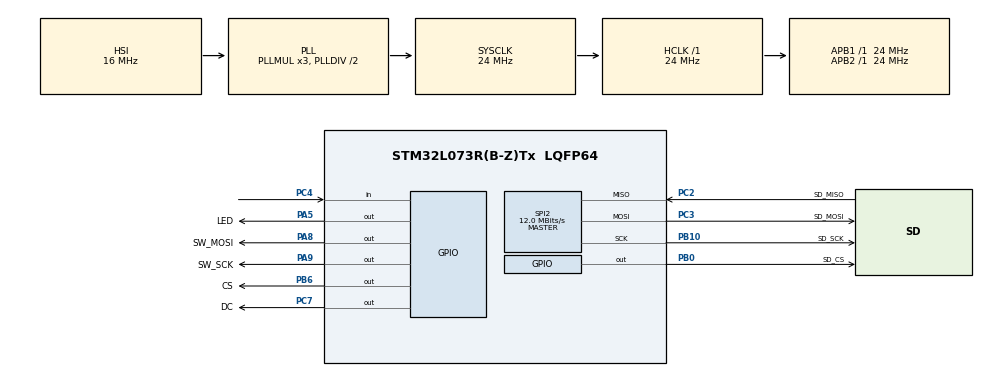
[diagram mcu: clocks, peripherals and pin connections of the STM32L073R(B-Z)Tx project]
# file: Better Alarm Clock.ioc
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FREERTOS.INCLUDE_uxTaskGetStackHighWaterMark=1
FREERTOS.INCLUDE_xEventGroupSetBitFromISR=1
FREERTOS.INCLUDE_xTimerPendFunctionCall=1
FREERTOS.MEMORY_ALLOCATION=1
FREERTOS.Tasks01=soundTask,3,128,soundTaskEntry,Default,NULL,Static,soundTaskBuffer,soundTaskControlBlock;guiTask,0,1024,guiTaskEntry,Default,NULL,Static,guiTaskBuffer,guiTaskControlBlock
FREERTOS.configCHECK_FOR_STACK_OVERFLOW=2
FREERTOS.configENABLE_BACKWARD_COMPATIBILITY=0
FREERTOS.configUSE_PREEMPTION=0
FREERTOS.configUSE_TASK_NOTIFICATIONS=0
FREERTOS.configUSE_TICKLESS_IDLE=1
FREERTOS.configUSE_TIMERS=1
Mcu.Family=STM32L0
Mcu.Name=STM32L073R(B-Z)Tx
Mcu.Package=LQFP64
NVIC.RTC_IRQn=true\:0\:0\:false\:false\:true\:false\:true
NVIC.TIM2_IRQn=true\:0\:0\:false\:false\:true\:false\:false
NVIC.TimeBase=TIM2_IRQn
NVIC.TimeBaseIP=TIM2
PA13.Mode=Serial_Wire
PA13.Signal=SYS_SWDIO
PA14.Mode=Serial_Wire
PA14.Signal=SYS_SWCLK
PA5.GPIO_Label=LED
PA5.Signal=GPIO_Output
PA8.GPIO_Label=SW_MOSI
PA8.Signal=GPIO_Output
PA9.GPIO_Label=SW_SCK
PA9.GPIO_PuPd=GPIO_PULLDOWN
PA9.GPIO_Speed=GPIO_SPEED_FREQ_VERY_HIGH
PA9.Signal=GPIO_Output
PB0.GPIO_Label=SD_CS
PB0.Signal=GPIO_Output
PB10.GPIO_Label=SD_SCK
PB10.Mode=Full_Duplex_Master
PB10.Signal=SPI2_SCK
PB6.GPIO_Label=CS
PB6.Signal=GPIO_Output
PC14-OSC32_IN.Mode=LSE-External-Oscillator
PC14-OSC32_IN.Signal=RCC_OSC32_IN
PC15-OSC32_OUT.Mode=LSE-External-Oscillator
PC15-OSC32_OUT.Signal=RCC_OSC32_OUT
PC2.GPIO_Label=SD_MISO
PC2.Mode=Full_Duplex_Master
PC2.Signal=SPI2_MISO
PC3.GPIO_Label=SD_MOSI
PC3.Mode=Full_Duplex_Master
PC3.Signal=SPI2_MOSI
PC4.Signal=GPIO_Input
PC7.GPIO_Label=DC
PC7.Signal=GPIO_Output
ProjectManager.HeapSize=0x200
ProjectManager.StackSize=0x400
ProjectManager.TargetToolchain=SW4STM32
RCC.AHBFreq_Value=24000000
RCC.APB1Freq_Value=24000000
RCC.APB1TimFreq_Value=24000000
RCC.APB2Freq_Value=24000000
RCC.APB2TimFreq_Value=24000000
RCC.HCLKFreq_Value=24000000
RCC.HSE_VALUE=8000000
RCC.HSI16_VALUE=16000000
RCC.HSI48_VALUE=48000000
RCC.HSI_VALUE=16000000
RCC.MSI_VALUE=2097000
RCC.RTCClockSelectionVirtual=RCC_RTCCLKSOURCE_LSE
RCC.SYSCLKFreq_VALUE=24000000
RCC.SYSCLKSource=RCC_SYSCLKSOURCE_PLLCLK
RCC.VCOOutputFreq_Value=48000000
RTC.Alarm-Alarm\ A=RTC_ALARM_A
RTC.AlarmMaskDateWeekDay-Alarm\ A=RTC_ALARMMASK_DATEWEEKDAY
RTC.AlarmMaskHours-Alarm\ A=RTC_ALARMMASK_HOURS
RTC.AlarmMaskMinutes-Alarm\ A=RTC_ALARMMASK_MINUTES
RTC.AlarmMaskSeconds-Alarm\ A=RTC_ALARMMASK_SECONDS
RTC.Alarm_B-Alarm\ B=RTC_ALARM_B
RTC.Format=RTC_FORMAT_BIN
SPI2.CalculateBaudRate=12.0 MBits/s
SPI2.Direction=SPI_DIRECTION_2LINES
SPI2.Mode=SPI_MODE_MASTER
SPI2.VirtualType=VM_MASTER
VP_FATFS_VS_Generic.Mode=User_defined
VP_FREERTOS_VS_ENABLE.Mode=Enabled
VP_RTC_VS_RTC_Activate.Mode=RTC_Enabled
VP_RTC_VS_RTC_Alarm_A_Intern.Mode=Alarm A
VP_RTC_VS_RTC_Alarm_B_Intern.Mode=Alarm B
VP_RTC_VS_RTC_Calendar.Mode=RTC_Calendar
VP_SYS_VS_tim2.Mode=TIM2
board=Better Alarm Clock

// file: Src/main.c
/**
  ******************************************************************************
  * File Name          : main.c
  * Description        : Main program body
  ******************************************************************************
  * This notice applies to any and all portions of this file
  * that are not between comment pairs USER CODE BEGIN and
  * USER CODE END. Other portions of this file, whether
  * inserted by the user or by software development tools
  * are owned by their respective copyright owners.
  *
  * Copyright (c) 2018 STMicroelectronics International N.V.
  * All rights reserved.
  *
  * Redistribution and use in source and binary forms, with or without
  * modification, are permitted, provided that the following conditions are met:
  *
  * 1. Redistribution of source code must retain the above copyright notice,
  *    this list of conditions and the following disclaimer.
  * 2. Redistributions in binary form must reproduce the above copyright notice,
  *    this list of conditions and the following disclaimer in the documentation
  *    and/or other materials provided with the distribution.
  * 3. Neither the name of STMicroelectronics nor the names of other
  *    contributors to this software may be used to endorse or promote products
  *    derived from this software without specific written permission.
  * 4. This software, including modifications and/or derivative works of this
  *    software, must execute solely and exclusively on microcontroller or
  *    microprocessor devices manufactured by or for STMicroelectronics.
  * 5. Redistribution and use of this software other than as permitted under
  *    this license is void and will automatically terminate your rights under
  *    this license.
  *
  * THIS SOFTWARE IS PROVIDED BY STMICROELECTRONICS AND CONTRIBUTORS "AS IS"
  * AND ANY EXPRESS, IMPLIED OR STATUTORY WARRANTIES, INCLUDING, BUT NOT
  * LIMITED TO, THE IMPLIED WARRANTIES OF MERCHANTABILITY, FITNESS FOR A
  * PARTICULAR PURPOSE AND NON-INFRINGEMENT OF THIRD PARTY INTELLECTUAL PROPERTY
  * RIGHTS ARE DISCLAIMED TO THE FULLEST EXTENT PERMITTED BY LAW. IN NO EVENT
  * SHALL STMICROELECTRONICS OR CONTRIBUTORS BE LIABLE FOR ANY DIRECT, INDIRECT,
  * INCIDENTAL, SPECIAL, EXEMPLARY, OR CONSEQUENTIAL DAMAGES (INCLUDING, BUT NOT
  * LIMITED TO, PROCUREMENT OF SUBSTITUTE GOODS OR SERVICES; LOSS OF USE, DATA,
  * OR PROFITS; OR BUSINESS INTERRUPTION) HOWEVER CAUSED AND ON ANY THEORY OF
  * LIABILITY, WHETHER IN CONTRACT, STRICT LIABILITY, OR TORT (INCLUDING
  * NEGLIGENCE OR OTHERWISE) ARISING IN ANY WAY OUT OF THE USE OF THIS SOFTWARE,
  * EVEN IF ADVISED OF THE POSSIBILITY OF SUCH DAMAGE.
  *
  ******************************************************************************
  */

#include "main.h"
#include "stm32l0xx_hal.h"
#include "cmsis_os.h"
#include "fatfs.h"

/* USER CODE BEGIN Includes */
#include "display_hw.h"
#include "application.h"
#include <stdio.h>	/*rtt*/
#include <stdlib.h>	/*rtt*/

/* USER CODE END Includes */

RTC_HandleTypeDef hrtc;

SPI_HandleTypeDef hspi2;

osThreadId soundTaskHandle;
uint32_t soundTaskBuffer[ 128 ];
osStaticThreadDef_t soundTaskControlBlock;
osThreadId guiTaskHandle;
uint32_t guiTaskBuffer[ 1024 ];
osStaticThreadDef_t guiTaskControlBlock;

/* USER CODE BEGIN PV */
/* Private variables ---------------------------------------------------------*/

/* USER CODE END PV */

void SystemClock_Config(void);
static void MX_GPIO_Init(void);
static void MX_RTC_Init(void);
static void MX_SPI2_Init(void);
void soundTaskEntry(void const * argument);
void guiTaskEntry(void const * argument);

/* USER CODE BEGIN PFP */
/* Private function prototypes -----------------------------------------------*/
extern void initialise_monitor_handles(void);	/*rtt*/
/* USER CODE END PFP */

int main(void)
{

  /* USER CODE BEGIN 1 */
  initialise_monitor_handles();

  puts("ARM semihosting enabled.");

  /* USER CODE END 1 */

  /* MCU Configuration----------------------------------------------------------*/

  /* Reset of all peripherals, Initializes the Flash interface and the Systick. */
  HAL_Init();

  /* Configure the system clock */
  SystemClock_Config();

  /* Initialize all configured peripherals */
  MX_GPIO_Init();
  MX_RTC_Init();
  MX_SPI2_Init();

  /* USER CODE BEGIN 2 */
  initDisplay();
  /* USER CODE END 2 */

  /* Create the thread(s) */
  /* definition and creation of soundTask */
  osThreadStaticDef(soundTask, soundTaskEntry, osPriorityRealtime, 0, 128, soundTaskBuffer, &soundTaskControlBlock);
  soundTaskHandle = osThreadCreate(osThread(soundTask), NULL);

  /* definition and creation of guiTask */
  osThreadStaticDef(guiTask, guiTaskEntry, osPriorityNormal, 0, 1024, guiTaskBuffer, &guiTaskControlBlock);
  guiTaskHandle = osThreadCreate(osThread(guiTask), NULL);

  /* Start scheduler */
  osKernelStart();

  /* We should never get here as control is now taken by the scheduler */

  /* Infinite loop */
  while (1)
  {

  }

}

/** System Clock Configuration
*/
void SystemClock_Config(void)
{

  RCC_OscInitTypeDef RCC_OscInitStruct;
  RCC_ClkInitTypeDef RCC_ClkInitStruct;
  RCC_PeriphCLKInitTypeDef PeriphClkInit;

    /**Configure the main internal regulator output voltage
    */
  __HAL_PWR_VOLTAGESCALING_CONFIG(PWR_REGULATOR_VOLTAGE_SCALE1);

    /**Configure LSE Drive Capability
    */
  __HAL_RCC_LSEDRIVE_CONFIG(RCC_LSEDRIVE_LOW);

    /**Initializes the CPU, AHB and APB busses clocks
    */
  RCC_OscInitStruct.OscillatorType = RCC_OSCILLATORTYPE_HSI|RCC_OSCILLATORTYPE_LSE;
  RCC_OscInitStruct.LSEState = RCC_LSE_ON;
  RCC_OscInitStruct.HSIState = RCC_HSI_ON;
  RCC_OscInitStruct.HSICalibrationValue = 16;
  RCC_OscInitStruct.PLL.PLLState = RCC_PLL_ON;
  RCC_OscInitStruct.PLL.PLLSource = RCC_PLLSOURCE_HSI;
  RCC_OscInitStruct.PLL.PLLMUL = RCC_PLLMUL_3;
  RCC_OscInitStruct.PLL.PLLDIV = RCC_PLLDIV_2;
  if (HAL_RCC_OscConfig(&RCC_OscInitStruct) != HAL_OK)
  {
    _Error_Handler(__FILE__, __LINE__);
  }

    /**Initializes the CPU, AHB and APB busses clocks
    */
  RCC_ClkInitStruct.ClockType = RCC_CLOCKTYPE_HCLK|RCC_CLOCKTYPE_SYSCLK
                              |RCC_CLOCKTYPE_PCLK1|RCC_CLOCKTYPE_PCLK2;
  RCC_ClkInitStruct.SYSCLKSource = RCC_SYSCLKSOURCE_PLLCLK;
  RCC_ClkInitStruct.AHBCLKDivider = RCC_SYSCLK_DIV1;
  RCC_ClkInitStruct.APB1CLKDivider = RCC_HCLK_DIV1;
  RCC_ClkInitStruct.APB2CLKDivider = RCC_HCLK_DIV1;

  if (HAL_RCC_ClockConfig(&RCC_ClkInitStruct, FLASH_LATENCY_1) != HAL_OK)
  {
    _Error_Handler(__FILE__, __LINE__);
  }

  PeriphClkInit.PeriphClockSelection = RCC_PERIPHCLK_RTC;
  PeriphClkInit.RTCClockSelection = RCC_RTCCLKSOURCE_LSE;
  if (HAL_RCCEx_PeriphCLKConfig(&PeriphClkInit) != HAL_OK)
  {
    _Error_Handler(__FILE__, __LINE__);
  }

    /**Configure the Systick interrupt time
    */
  HAL_SYSTICK_Config(HAL_RCC_GetHCLKFreq()/1000);

    /**Configure the Systick
    */
  HAL_SYSTICK_CLKSourceConfig(SYSTICK_CLKSOURCE_HCLK);

  /* SysTick_IRQn interrupt configuration */
  HAL_NVIC_SetPriority(SysTick_IRQn, 3, 0);
}

/* RTC init function */
static void MX_RTC_Init(void)
{

  RTC_TimeTypeDef sTime;
  RTC_DateTypeDef sDate;
  RTC_AlarmTypeDef sAlarm;

    /**Initialize RTC Only
    */
  hrtc.Instance = RTC;
  hrtc.Init.HourFormat = RTC_HOURFORMAT_24;
  hrtc.Init.AsynchPrediv = 127;
  hrtc.Init.SynchPrediv = 255;
  hrtc.Init.OutPut = RTC_OUTPUT_DISABLE;
  hrtc.Init.OutPutRemap = RTC_OUTPUT_REMAP_NONE;
  hrtc.Init.OutPutPolarity = RTC_OUTPUT_POLARITY_HIGH;
  hrtc.Init.OutPutType = RTC_OUTPUT_TYPE_OPENDRAIN;
  if (HAL_RTC_Init(&hrtc) != HAL_OK)
  {
    _Error_Handler(__FILE__, __LINE__);
  }

    /**Initialize RTC and set the Time and Date
    */
  if(HAL_RTCEx_BKUPRead(&hrtc, RTC_BKP_DR0) != 0x32F2){
  sTime.Hours = 0;
  sTime.Minutes = 0;
  sTime.Seconds = 0;
  sTime.DayLightSaving = RTC_DAYLIGHTSAVING_NONE;
  sTime.StoreOperation = RTC_STOREOPERATION_RESET;
  if (HAL_RTC_SetTime(&hrtc, &sTime, RTC_FORMAT_BIN) != HAL_OK)
  {
    _Error_Handler(__FILE__, __LINE__);
  }

  sDate.WeekDay = RTC_WEEKDAY_MONDAY;
  sDate.Month = RTC_MONTH_JANUARY;
  sDate.Date = 1;
  sDate.Year = 0;

  if (HAL_RTC_SetDate(&hrtc, &sDate, RTC_FORMAT_BIN) != HAL_OK)
  {
    _Error_Handler(__FILE__, __LINE__);
  }

    HAL_RTCEx_BKUPWrite(&hrtc,RTC_BKP_DR0,0x32F2);
  }
    /**Enable the Alarm A
    */
  sAlarm.AlarmTime.Hours = 0;
  sAlarm.AlarmTime.Minutes = 0;
  sAlarm.AlarmTime.Seconds = 0;
  sAlarm.AlarmTime.SubSeconds = 0;
  sAlarm.AlarmTime.DayLightSaving = RTC_DAYLIGHTSAVING_NONE;
  sAlarm.AlarmTime.StoreOperation = RTC_STOREOPERATION_RESET;
  sAlarm.AlarmMask = RTC_ALARMMASK_ALL;
  sAlarm.AlarmSubSecondMask = RTC_ALARMSUBSECONDMASK_ALL;
  sAlarm.AlarmDateWeekDaySel = RTC_ALARMDATEWEEKDAYSEL_DATE;
  sAlarm.AlarmDateWeekDay = 1;
  sAlarm.Alarm = RTC_ALARM_A;
  if (HAL_RTC_SetAlarm_IT(&hrtc, &sAlarm, RTC_FORMAT_BIN) != HAL_OK)
  {
    _Error_Handler(__FILE__, __LINE__);
  }

    /**Enable the Alarm B
    */
  sAlarm.AlarmMask = RTC_ALARMMASK_NONE;
  sAlarm.AlarmDateWeekDay = 1;
  sAlarm.Alarm = RTC_ALARM_B;
  if (HAL_RTC_SetAlarm_IT(&hrtc, &sAlarm, RTC_FORMAT_BIN) != HAL_OK)
  {
    _Error_Handler(__FILE__, __LINE__);
  }

}

/* SPI2 init function */
static void MX_SPI2_Init(void)
{

  /* SPI2 parameter configuration*/
  hspi2.Instance = SPI2;
  hspi2.Init.Mode = SPI_MODE_MASTER;
  hspi2.Init.Direction = SPI_DIRECTION_2LINES;
  hspi2.Init.DataSize = SPI_DATASIZE_8BIT;
  hspi2.Init.CLKPolarity = SPI_POLARITY_LOW;
  hspi2.Init.CLKPhase = SPI_PHASE_1EDGE;
  hspi2.Init.NSS = SPI_NSS_SOFT;
  hspi2.Init.BaudRatePrescaler = SPI_BAUDRATEPRESCALER_2;
  hspi2.Init.FirstBit = SPI_FIRSTBIT_MSB;
  hspi2.Init.TIMode = SPI_TIMODE_DISABLE;
  hspi2.Init.CRCCalculation = SPI_CRCCALCULATION_DISABLE;
  hspi2.Init.CRCPolynomial = 7;
  if (HAL_SPI_Init(&hspi2) != HAL_OK)
  {
    _Error_Handler(__FILE__, __LINE__);
  }

}

/** Configure pins as
        * Analog
        * Input
        * Output
        * EVENT_OUT
        * EXTI
        * Free pins are configured automatically as Analog (this feature is enabled through
        * the Code Generation settings)
*/
static void MX_GPIO_Init(void)
{

  GPIO_InitTypeDef GPIO_InitStruct;

  /* GPIO Ports Clock Enable */
  __HAL_RCC_GPIOC_CLK_ENABLE();
  __HAL_RCC_GPIOH_CLK_ENABLE();
  __HAL_RCC_GPIOA_CLK_ENABLE();
  __HAL_RCC_GPIOB_CLK_ENABLE();
  __HAL_RCC_GPIOD_CLK_ENABLE();

  /*Configure GPIO pin Output Level */
  HAL_GPIO_WritePin(GPIOA, LED_Pin|SW_MOSI_Pin|SW_SCK_Pin, GPIO_PIN_RESET);

  /*Configure GPIO pin Output Level */
  HAL_GPIO_WritePin(GPIOB, SD_CS_Pin|CS_Pin, GPIO_PIN_RESET);

  /*Configure GPIO pin Output Level */
  HAL_GPIO_WritePin(DC_GPIO_Port, DC_Pin, GPIO_PIN_RESET);

  /*Configure GPIO pins : PC13 PC0 PC1 PC5
                           PC6 PC8 PC9 PC10
                           PC11 PC12 */
  GPIO_InitStruct.Pin = GPIO_PIN_13|GPIO_PIN_0|GPIO_PIN_1|GPIO_PIN_5
                          |GPIO_PIN_6|GPIO_PIN_8|GPIO_PIN_9|GPIO_PIN_10
                          |GPIO_PIN_11|GPIO_PIN_12;
  GPIO_InitStruct.Mode = GPIO_MODE_ANALOG;
  GPIO_InitStruct.Pull = GPIO_NOPULL;
  HAL_GPIO_Init(GPIOC, &GPIO_InitStruct);

  /*Configure GPIO pins : PH0 PH1 */
  GPIO_InitStruct.Pin = GPIO_PIN_0|GPIO_PIN_1;
  GPIO_InitStruct.Mode = GPIO_MODE_ANALOG;
  GPIO_InitStruct.Pull = GPIO_NOPULL;
  HAL_GPIO_Init(GPIOH, &GPIO_InitStruct);

  /*Configure GPIO pins : PA0 PA1 PA2 PA3
                           PA4 PA6 PA7 PA10
                           PA11 PA12 PA15 */
  GPIO_InitStruct.Pin = GPIO_PIN_0|GPIO_PIN_1|GPIO_PIN_2|GPIO_PIN_3
                          |GPIO_PIN_4|GPIO_PIN_6|GPIO_PIN_7|GPIO_PIN_10
                          |GPIO_PIN_11|GPIO_PIN_12|GPIO_PIN_15;
  GPIO_InitStruct.Mode = GPIO_MODE_ANALOG;
  GPIO_InitStruct.Pull = GPIO_NOPULL;
  HAL_GPIO_Init(GPIOA, &GPIO_InitStruct);

  /*Configure GPIO pins : LED_Pin SW_MOSI_Pin */
  GPIO_InitStruct.Pin = LED_Pin|SW_MOSI_Pin;
  GPIO_InitStruct.Mode = GPIO_MODE_OUTPUT_PP;
  GPIO_InitStruct.Pull = GPIO_NOPULL;
  GPIO_InitStruct.Speed = GPIO_SPEED_FREQ_LOW;
  HAL_GPIO_Init(GPIOA, &GPIO_InitStruct);

  /*Configure GPIO pin : PC4 */
  GPIO_InitStruct.Pin = GPIO_PIN_4;
  GPIO_InitStruct.Mode = GPIO_MODE_INPUT;
  GPIO_InitStruct.Pull = GPIO_NOPULL;
  HAL_GPIO_Init(GPIOC, &GPIO_InitStruct);

  /*Configure GPIO pins : SD_CS_Pin CS_Pin */
  GPIO_InitStruct.Pin = SD_CS_Pin|CS_Pin;
  GPIO_InitStruct.Mode = GPIO_MODE_OUTPUT_PP;
  GPIO_InitStruct.Pull = GPIO_NOPULL;
  GPIO_InitStruct.Speed = GPIO_SPEED_FREQ_LOW;
  HAL_GPIO_Init(GPIOB, &GPIO_InitStruct);

  /*Configure GPIO pins : PB1 PB2 PB11 PB12
                           PB13 PB14 PB15 PB3
                           PB4 PB5 PB7 PB8
                           PB9 */
  GPIO_InitStruct.Pin = GPIO_PIN_1|GPIO_PIN_2|GPIO_PIN_11|GPIO_PIN_12
                          |GPIO_PIN_13|GPIO_PIN_14|GPIO_PIN_15|GPIO_PIN_3
                          |GPIO_PIN_4|GPIO_PIN_5|GPIO_PIN_7|GPIO_PIN_8
                          |GPIO_PIN_9;
  GPIO_InitStruct.Mode = GPIO_MODE_ANALOG;
  GPIO_InitStruct.Pull = GPIO_NOPULL;
  HAL_GPIO_Init(GPIOB, &GPIO_InitStruct);

  /*Configure GPIO pin : DC_Pin */
  GPIO_InitStruct.Pin = DC_Pin;
  GPIO_InitStruct.Mode = GPIO_MODE_OUTPUT_PP;
  GPIO_InitStruct.Pull = GPIO_NOPULL;
  GPIO_InitStruct.Speed = GPIO_SPEED_FREQ_LOW;
  HAL_GPIO_Init(DC_GPIO_Port, &GPIO_InitStruct);

  /*Configure GPIO pin : SW_SCK_Pin */
  GPIO_InitStruct.Pin = SW_SCK_Pin;
  GPIO_InitStruct.Mode = GPIO_MODE_OUTPUT_PP;
  GPIO_InitStruct.Pull = GPIO_PULLDOWN;
  GPIO_InitStruct.Speed = GPIO_SPEED_FREQ_VERY_HIGH;
  HAL_GPIO_Init(SW_SCK_GPIO_Port, &GPIO_InitStruct);

  /*Configure GPIO pin : PD2 */
  GPIO_InitStruct.Pin = GPIO_PIN_2;
  GPIO_InitStruct.Mode = GPIO_MODE_ANALOG;
  GPIO_InitStruct.Pull = GPIO_NOPULL;
  HAL_GPIO_Init(GPIOD, &GPIO_InitStruct);

}

/* USER CODE BEGIN 4 */
/**
  * @brief  Pre Sleep Processing
  * @param  ulExpectedIdleTime: Expected time in idle state
  * @retval None
  */
void PreSleepProcessing(uint32_t * ulExpectedIdleTime)
{
  /* Called by the kernel before it places the MCU into a sleep mode because
  configPRE_SLEEP_PROCESSING() is #defined to PreSleepProcessing().

  NOTE:  Additional actions can be taken here to get the power consumption
  even lower.  For example, peripherals can be turned off here, and then back
  on again in the post sleep processing function.  For maximum power saving
  ensure all unused pins are in their lowest power state. */

  /*
    (*ulExpectedIdleTime) is set to 0 to indicate that PreSleepProcessing contains
    its own wait for interrupt or wait for event instruction and so the kernel vPortSuppressTicksAndSleep
    function does not need to execute the wfi instruction
  */
  *ulExpectedIdleTime = 0;

  /*Enter to sleep Mode using the HAL function HAL_PWR_EnterSLEEPMode with WFI instruction*/
  HAL_PWR_EnterSLEEPMode(PWR_MAINREGULATOR_ON, PWR_SLEEPENTRY_WFI);
}

/**
  * @brief  Post Sleep Processing
  * @param  ulExpectedIdleTime: Not used
  * @retval None
  */
void PostSleepProcessing(uint32_t * ulExpectedIdleTime)
{
  /* Called by the kernel when the MCU exits a sleep mode because
  configPOST_SLEEP_PROCESSING is #defined to PostSleepProcessing(). */

  /* Avoid compiler warnings about the unused parameter. */
  (void) ulExpectedIdleTime;
}

/* USER CODE END 4 */

/* soundTaskEntry function */
void soundTaskEntry(void const * argument)
{
  FRESULT res;                                          /* FatFs function common result code */
  uint32_t byteswritten, bytesread;                     /* File write/read counts */
  uint8_t wtext[] = "This is STM32 working with FatFs"; /* File write buffer */
  uint8_t rtext[100];                                   /* File read buffer */

  /* init code for FATFS */
  MX_FATFS_Init();

  /*## Create and Open a new text file object with write access #######*/
  if(f_open(&USERFile, "STM32.TXT", FA_CREATE_ALWAYS | FA_WRITE) != FR_OK)
    {
      /* 'STM32.TXT' file Open for write Error */
      Error_Handler();
    }
  else
    {
      /*##-4- Write data to the text file ##################################*/
      res = f_write(&USERFile, wtext, sizeof(wtext), (void *)&byteswritten);

      if((byteswritten == 0) || (res != FR_OK))
	{
	  /* 'STM32.TXT' file Write or EOF Error */
	  Error_Handler();
	}
      else
	{
	  /*##-5- Close the open text file ###################################*/
	  f_close(&USERFile);

	  /*##-6- Open the text file object with read access #################*/
	  if(f_open(&USERFile, "STM32.TXT", FA_READ) != FR_OK)
	    {
	      /* 'STM32.TXT' file Open for read Error */
	      Error_Handler();
	    }
	  else
	    {
	      /*##-7- Read data from the text file #############################*/
	      res = f_read(&USERFile, rtext, sizeof(rtext), (UINT*)&bytesread);

	      if((bytesread == 0) || (res != FR_OK))
		{
		  /* 'STM32.TXT' file Read or EOF Error */
		  Error_Handler();
		}
	      else
		{
		  /*##-8- Close the open text file ###############################*/
		  f_close(&USERFile);

		  /*##-9- Compare read data with the expected data ###############*/
		  if((bytesread != byteswritten))
		    {
		      /* Read data is different from the expected data */
		      Error_Handler();
		    }
		  else
		    {
		      /* Success of the demo: no error occurrence */

		    }
		}
	    }
	}
    }

  /*##-10- Unlink the SD disk I/O driver #####################################*/
  //FATFS_UnLinkDriver(SDPath);

  /* USER CODE BEGIN 5 */
  /* Infinite loop */
  for(;;)
    {
      printf("In the sound task...\n");
      osDelay(1000);
    }
  /* USER CODE END 5 */
}

/* guiTaskEntry function */
void guiTaskEntry(void const * argument)
{
  /* USER CODE BEGIN guiTaskEntry */
  runGUITask();
  /* USER CODE END guiTaskEntry */
}

void HAL_TIM_PeriodElapsedCallback(TIM_HandleTypeDef *htim)
{
  if (htim->Instance == TIM2) {
    HAL_IncTick();
  }
}

void _Error_Handler(char * file, int line)
{
  while(1)
  {
  }
}

/************************ (C) COPYRIGHT STMicroelectronics *****END OF FILE****/

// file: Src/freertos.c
/**
  ******************************************************************************
  * File Name          : freertos.c
  * Description        : Code for freertos applications
  ******************************************************************************
  * This notice applies to any and all portions of this file
  * that are not between comment pairs USER CODE BEGIN and
  * USER CODE END. Other portions of this file, whether
  * inserted by the user or by software development tools
  * are owned by their respective copyright owners.
  *
  * Copyright (c) 2018 STMicroelectronics International N.V.
  * All rights reserved.
  *
  * Redistribution and use in source and binary forms, with or without
  * modification, are permitted, provided that the following conditions are met:
  *
  * 1. Redistribution of source code must retain the above copyright notice,
  *    this list of conditions and the following disclaimer.
  * 2. Redistributions in binary form must reproduce the above copyright notice,
  *    this list of conditions and the following disclaimer in the documentation
  *    and/or other materials provided with the distribution.
  * 3. Neither the name of STMicroelectronics nor the names of other
  *    contributors to this software may be used to endorse or promote products
  *    derived from this software without specific written permission.
  * 4. This software, including modifications and/or derivative works of this
  *    software, must execute solely and exclusively on microcontroller or
  *    microprocessor devices manufactured by or for STMicroelectronics.
  * 5. Redistribution and use of this software other than as permitted under
  *    this license is void and will automatically terminate your rights under
  *    this license.
  *
  * THIS SOFTWARE IS PROVIDED BY STMICROELECTRONICS AND CONTRIBUTORS "AS IS"
  * AND ANY EXPRESS, IMPLIED OR STATUTORY WARRANTIES, INCLUDING, BUT NOT
  * LIMITED TO, THE IMPLIED WARRANTIES OF MERCHANTABILITY, FITNESS FOR A
  * PARTICULAR PURPOSE AND NON-INFRINGEMENT OF THIRD PARTY INTELLECTUAL PROPERTY
  * RIGHTS ARE DISCLAIMED TO THE FULLEST EXTENT PERMITTED BY LAW. IN NO EVENT
  * SHALL STMICROELECTRONICS OR CONTRIBUTORS BE LIABLE FOR ANY DIRECT, INDIRECT,
  * INCIDENTAL, SPECIAL, EXEMPLARY, OR CONSEQUENTIAL DAMAGES (INCLUDING, BUT NOT
  * LIMITED TO, PROCUREMENT OF SUBSTITUTE GOODS OR SERVICES; LOSS OF USE, DATA,
  * OR PROFITS; OR BUSINESS INTERRUPTION) HOWEVER CAUSED AND ON ANY THEORY OF
  * LIABILITY, WHETHER IN CONTRACT, STRICT LIABILITY, OR TORT (INCLUDING
  * NEGLIGENCE OR OTHERWISE) ARISING IN ANY WAY OUT OF THE USE OF THIS SOFTWARE,
  * EVEN IF ADVISED OF THE POSSIBILITY OF SUCH DAMAGE.
  *
  ******************************************************************************
  */

#include "FreeRTOS.h"
#include "task.h"

/* Pre/Post sleep processing prototypes */
void PreSleepProcessing(uint32_t *ulExpectedIdleTime);
void PostSleepProcessing(uint32_t *ulExpectedIdleTime);

/* Hook prototypes */

/* USER CODE BEGIN PREPOSTSLEEP */
__weak void PreSleepProcessing(uint32_t *ulExpectedIdleTime)
{
/* place for user code */
}

__weak void PostSleepProcessing(uint32_t *ulExpectedIdleTime)
{
/* place for user code */
}
/* USER CODE END PREPOSTSLEEP */

/************************ (C) COPYRIGHT STMicroelectronics *****END OF FILE****/
